# MMIOFixture register map
File version: 1
Software-only bus word fixture
Registers are 32-bit, read-write, no defined reset value unless marked. A register's access mark holds for its fields unless they carry their own. Offsets are from the block's base; lines under a group give offsets from that group; [hi:lo] are bit positions; {n}, {i} and the like mark numbered series; 'fields as' and 'values as' point back to an identical list; <NAME> marks a mode.

## Memory map
0x40000000 PORT

## PORT
Base 0x40000000
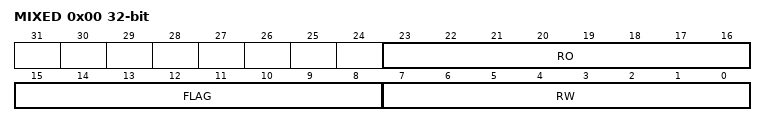
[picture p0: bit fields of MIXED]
0x00 MIXED
  [23:16] RO ro, [15:8] FLAG write-1-clears, [7:0] RW
0x04 WO wo
0x08 READ_CLEAR read-clears
0x10 WIDE 64-bit
